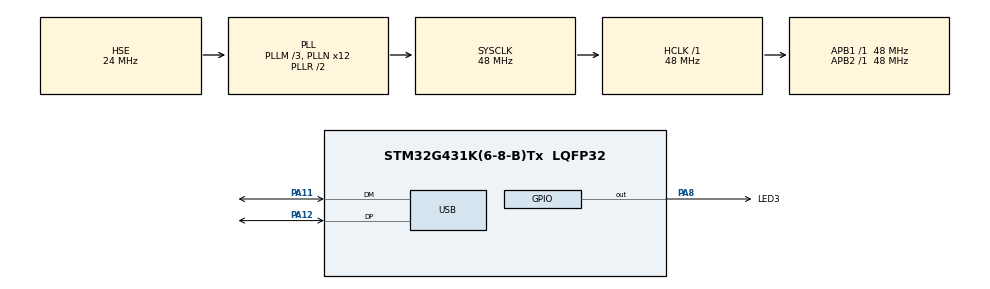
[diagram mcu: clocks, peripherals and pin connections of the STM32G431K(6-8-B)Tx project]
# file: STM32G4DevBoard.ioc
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Mcu.Family=STM32G4
Mcu.Name=STM32G431K(6-8-B)Tx
Mcu.Package=LQFP32
NVIC.PriorityGroup=NVIC_PRIORITYGROUP_4
NVIC.USB_HP_IRQn=true\:0\:0\:false\:false\:true\:true\:true
NVIC.USB_LP_IRQn=true\:0\:0\:false\:false\:true\:true\:true
PA11.Mode=Device
PA11.Signal=USB_DM
PA12.Mode=Device
PA12.Signal=USB_DP
PA8.GPIO_Label=LED3
PA8.Signal=GPIO_Output
PF0-OSC_IN.Mode=HSE-External-Oscillator
PF0-OSC_IN.Signal=RCC_OSC_IN
PF1-OSC_OUT.Mode=HSE-External-Oscillator
PF1-OSC_OUT.Signal=RCC_OSC_OUT
ProjectManager.HeapSize=0x400
ProjectManager.StackSize=0x800
ProjectManager.TargetToolchain=SW4STM32
RCC.ADC12Freq_Value=48000000
RCC.AHBFreq_Value=48000000
RCC.APB1Freq_Value=48000000
RCC.APB1TimFreq_Value=48000000
RCC.APB2Freq_Value=48000000
RCC.APB2TimFreq_Value=48000000
RCC.CortexFreq_Value=48000000
RCC.EXTERNAL_CLOCK_VALUE=12288000
RCC.HCLKFreq_Value=48000000
RCC.HSE_VALUE=24000000
RCC.HSI48_VALUE=48000000
RCC.HSI_VALUE=16000000
RCC.LSE_VALUE=32768
RCC.PLLM=RCC_PLLM_DIV3
RCC.PLLN=12
RCC.PLLSourceVirtual=RCC_PLLSOURCE_HSE
RCC.SYSCLKFreq_VALUE=48000000
RCC.SYSCLKSource=RCC_SYSCLKSOURCE_PLLCLK
RCC.USBFreq_Value=48000000
RCC.VCOOutputFreq_Value=96000000
USB_DEVICE.CLASS_NAME_FS=CDC
USB_DEVICE.VirtualMode=Cdc
USB_DEVICE.VirtualModeFS=Cdc_FS
VP_SYS_VS_DBSignals.Mode=DisableDeadBatterySignals
VP_USB_DEVICE_VS_USB_DEVICE_CDC_FS.Mode=CDC_FS
board=NUCLEO-L432KC

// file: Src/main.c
/* USER CODE BEGIN Header */
/**
  ******************************************************************************
  * @file           : main.c
  * @brief          : Main program body
  ******************************************************************************
  * @attention
  *
  * <h2><center>&copy; Copyright (c) 2020 STMicroelectronics.
  * All rights reserved.</center></h2>
  *
  * This software component is licensed by ST under BSD 3-Clause license,
  * the "License"; You may not use this file except in compliance with the
  * License. You may obtain a copy of the License at:
  *                        opensource.org/licenses/BSD-3-Clause
  *
  ******************************************************************************
  */
/* USER CODE END Header */

#include "main.h"
#include "usb_device.h"

void SystemClock_Config(void);
static void MX_GPIO_Init(void);

int main(void)
{

  /* MCU Configuration--------------------------------------------------------*/

  /* Reset of all peripherals, Initializes the Flash interface and the Systick. */
  HAL_Init();

  /* Configure the system clock */
  SystemClock_Config();

  /* Initialize all configured peripherals */
  MX_GPIO_Init();
  MX_USB_Device_Init();

  /* Infinite loop */
  /* USER CODE BEGIN WHILE */
  while (1)
  {
		HAL_GPIO_TogglePin(LED3_GPIO_Port,LED3_Pin);
		HAL_Delay(1000);
    /* USER CODE END WHILE */

  }
}

void SystemClock_Config(void)
{
  RCC_OscInitTypeDef RCC_OscInitStruct = {0};
  RCC_ClkInitTypeDef RCC_ClkInitStruct = {0};
  RCC_PeriphCLKInitTypeDef PeriphClkInit = {0};

  /** Configure the main internal regulator output voltage
  */
  HAL_PWREx_ControlVoltageScaling(PWR_REGULATOR_VOLTAGE_SCALE1);
  /** Initializes the CPU, AHB and APB busses clocks
  */
  RCC_OscInitStruct.OscillatorType = RCC_OSCILLATORTYPE_HSE;
  RCC_OscInitStruct.HSEState = RCC_HSE_ON;
  RCC_OscInitStruct.PLL.PLLState = RCC_PLL_ON;
  RCC_OscInitStruct.PLL.PLLSource = RCC_PLLSOURCE_HSE;
  RCC_OscInitStruct.PLL.PLLM = RCC_PLLM_DIV3;
  RCC_OscInitStruct.PLL.PLLN = 12;
  RCC_OscInitStruct.PLL.PLLP = RCC_PLLP_DIV2;
  RCC_OscInitStruct.PLL.PLLQ = RCC_PLLQ_DIV2;
  RCC_OscInitStruct.PLL.PLLR = RCC_PLLR_DIV2;
  if (HAL_RCC_OscConfig(&RCC_OscInitStruct) != HAL_OK)
  {
    Error_Handler();
  }
  /** Initializes the CPU, AHB and APB busses clocks
  */
  RCC_ClkInitStruct.ClockType = RCC_CLOCKTYPE_HCLK|RCC_CLOCKTYPE_SYSCLK
                              |RCC_CLOCKTYPE_PCLK1|RCC_CLOCKTYPE_PCLK2;
  RCC_ClkInitStruct.SYSCLKSource = RCC_SYSCLKSOURCE_PLLCLK;
  RCC_ClkInitStruct.AHBCLKDivider = RCC_SYSCLK_DIV1;
  RCC_ClkInitStruct.APB1CLKDivider = RCC_HCLK_DIV1;
  RCC_ClkInitStruct.APB2CLKDivider = RCC_HCLK_DIV1;

  if (HAL_RCC_ClockConfig(&RCC_ClkInitStruct, FLASH_LATENCY_2) != HAL_OK)
  {
    Error_Handler();
  }
  /** Initializes the peripherals clocks
  */
  PeriphClkInit.PeriphClockSelection = RCC_PERIPHCLK_USB;
  PeriphClkInit.UsbClockSelection = RCC_USBCLKSOURCE_PLL;
  if (HAL_RCCEx_PeriphCLKConfig(&PeriphClkInit) != HAL_OK)
  {
    Error_Handler();
  }
}

static void MX_GPIO_Init(void)
{
  GPIO_InitTypeDef GPIO_InitStruct = {0};

  /* GPIO Ports Clock Enable */
  __HAL_RCC_GPIOF_CLK_ENABLE();
  __HAL_RCC_GPIOA_CLK_ENABLE();

  /*Configure GPIO pin Output Level */
  HAL_GPIO_WritePin(LED3_GPIO_Port, LED3_Pin, GPIO_PIN_RESET);

  /*Configure GPIO pin : LED3_Pin */
  GPIO_InitStruct.Pin = LED3_Pin;
  GPIO_InitStruct.Mode = GPIO_MODE_OUTPUT_PP;
  GPIO_InitStruct.Pull = GPIO_NOPULL;
  GPIO_InitStruct.Speed = GPIO_SPEED_FREQ_LOW;
  HAL_GPIO_Init(LED3_GPIO_Port, &GPIO_InitStruct);

}

void Error_Handler(void)
{
}

/************************ (C) COPYRIGHT STMicroelectronics *****END OF FILE****/
